# MU3E_MUTRIG_INJECTOR register map
Vendor: Mu3e; Series: MU3E_FPGA_IP; File version: 26.0.2.0429
CSR description for the active MuTRiG timestamp precision injector. This SVD matches mutrig_injector_multiheader.vhd and the Phase-5 mutrig_injector_0 instance.
Registers are 32-bit, read-write, reset 0x0 unless marked. A register's access mark holds for its fields unless they carry their own. Offsets are from the block's base; lines under a group give offsets from that group; [hi:lo] are bit positions; {n}, {i} and the like mark numbered series; 'fields as' and 'values as' point back to an identical list; <NAME> marks a mode.

## Memory map
0x00000000 MUTRIG_INJECTOR_CSR size 0x40 — Relative 16-word control/status aperture for the MuTRiG injector.

## MUTRIG_INJECTOR_CSR — Relative 16-word control/status aperture for the MuTRiG injector.
Base 0x00000000
0x00 MODE — Injection mode selector. Writing value 4 emits a one-click pulse and stores mode 0. Writing value 5 also reseeds PRBS state.
  [3:0] mode — 0=off/one-click return, 1=header synchronous, 2=periodic main clock, 3=periodic oscillator clock, 4=one-click command, 5=PRBS random.
0x04 HEADER_DELAY reset 0x64 — Main-clock delay from selected header match to first header-synchronous pulse.
  [31:0] cycles — Header delay in clock_interface cycles.
0x08 HEADER_INTERVAL reset 0x1 — Number of selected header matches between mode-1 bursts.
  [31:0] matches — Selected-header match interval.
0x0C INJECTION_MULTIPLICITY reset 0x1 — Number of pulses in each header-triggered or PRBS-triggered burst.
  [31:0] count — Pulse count per burst.
0x10 HEADER_CH — Selected header channel. The RTL compares this value against all eight headerinfo channel sidebands.
  [7:0] channel — Selected header channel. Width is set by HEADERINFO_CHANNEL_W in Platform Designer.
0x14 PULSE_INTERVAL reset 0x3E8 — Mode-2 interval in main-clock cycles. Mode 3 derives the oscillator-domain interval from this value.
  [31:0] cycles — Pulse period before mode-3 clock-domain scaling.
0x18 PULSE_HIGH_CYCLES reset 0x5 — Pulse high duration. RTL uses bits [7:0] and enforces a minimum low gap between burst pulses.
  [7:0] cycles — Pulse high duration in cycles.
0x1C PRBS_RATE reset 0x3E7 — Number of main-clock cycles between PRBS state advances in mode 5.
  [31:0] cycles — PRBS advance interval.
0x20 PRBS_PATTERN reset 0x1 — Pattern compared against the low PRBS bits selected by PRBS_CTRL.
  [31:0] pattern — Pattern bits used for PRBS match.
0x24 PRBS_SEED reset 0xACE1 — Seed used when entering or reseeding mode 5. All-zero selected bits are sanitized to bit 0 set.
  [31:0] seed — PRBS seed word.
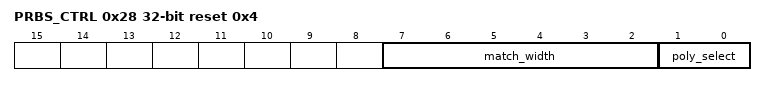
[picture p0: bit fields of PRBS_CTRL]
0x28 PRBS_CTRL reset 0x4 — PRBS polynomial and match-width selector.
  [7:2] match_width — Number of low PRBS bits compared against PRBS_PATTERN, clipped to selected polynomial width. Zero is treated as one.
  [1:0] poly_select — 0=PRBS7, 1=PRBS15, 2=PRBS23, 3=PRBS31.
{0x0+4i} RESERVED{i} (i=11..15) ro — Reserved decoded word. Current RTL returns zero and ignores writes.
  [31:0] value — Reserved zero readback.
